# pse84_a0 register map
Vendor: Infineon Technologies; Series: PSE84_A0; File version: 1.0
CPU: CM33 r0p1, little endian, MPU, FPU, VTOR, 3 interrupt priority bits
Registers are 32-bit, read-write, reset 0x0 unless marked. A register's access mark holds for its fields unless they carry their own. Offsets are from the block's base; [hi:lo] are bit positions; lines under a group give offsets from that group.

## USBHS (part 1 of 7) — Regmap for both Subsystem and Controller IP
Base 0x44900000
0x00 DWC_OTG_INTREG group — Internal register map
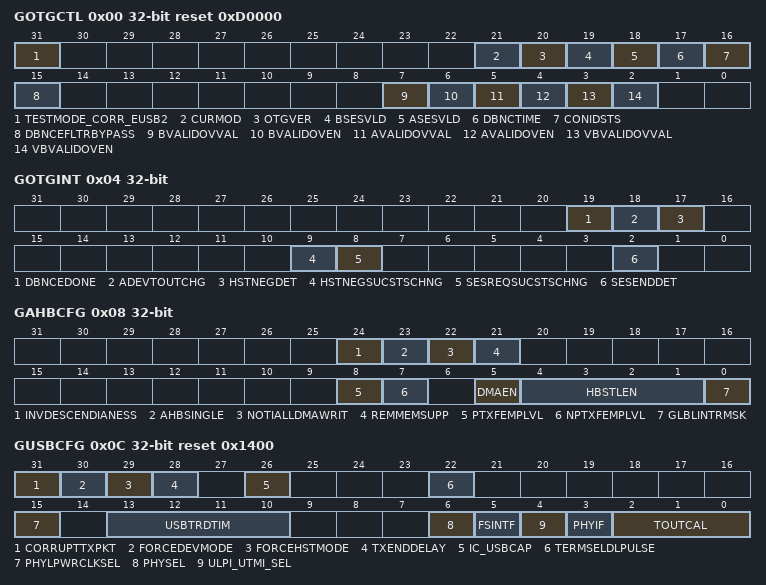
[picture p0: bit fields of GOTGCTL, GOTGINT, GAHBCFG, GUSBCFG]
  0x00 GOTGCTL reset 0xD0000 — The OTG Control and Status register controls the behavior and reflects the status of the OTG function of the controller.
    [31] TESTMODE_CORR_EUSB2 — UTMI IF correction for eUSB2 PHY during Test mode This bit is used to modify the behavior of UTMI 8-bit interface signals during test J and test K sequences when eUSB2 PHY is used. When this bit is set to 1'b1, the controller asserts utmi_txvalid and utmi_opmode in the same cycle during test J or test K sequence execution. Note: This bit is applicable only if eUSB2 PHY is used with 8-bit UTMI interface.
      0=eUSB2_corr_disable (The controller asserts utmi_txvalid one cycle later than utmi_opmode.); 1=eUSB2_corr_enable (The controller asserts utmi_txvalid and utmi_opmode in the same cycle.)
    [21] CURMOD ro — Current Mode of Operation (CurMod) Mode: Host and Device Indicates the current mode. - 1'b0: Device mode - 1'b1: Host mode Reset: - 1'b1 in Host-only mode (OTG_MODE=5 or 6) - 1'b0 in all other configurations Note: The reset value of this register field can be read only after the PHY clock is stable, or if IDDIG_FILTER is enabled, wait for the filter timer to expire to read the correct reset value which ever event is later.
      0=DEVICEMODE (Current mode is device mode.); 1=HOSTMODE (Current mode is host mode.)
    [20] OTGVER — OTG Version (OTGVer) Indicates the OTG revision. - 1'b0: OTG Version 1.3. In this version the core supports Data line pulsing and VBus pulsing for SRP. - 1'b1: OTG Version 2.0. In this version the core supports only Data line pulsing for SRP.
      0=VER13 (Supports OTG Version 1.3); 1=VER20 (Supports OTG Version 2.0)
    [19] BSESVLD ro — Mode: Device only B-Session Valid (BSesVld) Indicates the Device mode transceiver status. - 1'b0: B-session is not valid. - 1'b1: B-session is valid. In OTG mode, you can use this bit to determine if the device is connected or disconnected. Note: - If you do not enable OTG features (such as SRP and HNP), the read reset value will be 1.The vbus assigns the values internally for non- SRP or non-HNP configurations. - In case of OTG_MODE=0, the reset value of this bit is 1'b0. - The reset value of this register field can be read only after the PHY clock is stable, or if IDDIG_FILTER is enabled, wait for the filter timer to expire to read the correct reset value which ever event is later.
      0=NOTVALID (B-session is not valid.); 1=VALID (B-session is valid.)
    [18] ASESVLD ro — Mode: Host only A-Session Valid (ASesVld) Indicates the Host mode transceiver status. - 1'b0: A-session is not valid - 1'b1: A-session is valid Note: If you do not enabled OTG features (such as SRP and HNP), the read reset value will be 1. The vbus assigns the values internally for non-SRP or non-HNP configurations. In case of OTG_MODE=0, the reset value of this bit is 1'b0.
      0=NOTVALID (A-session is not valid.); 1=VALID (A-session is valid.)
    [17] DBNCTIME ro — Mode: Host only Long/Short Debounce Time (DbncTime) Indicates the debounce time of a detected connection. - 1'b0: Long debounce time, used for physical connections (100 ms + 2.5 micro-sec) - 1'b1: Short debounce time, used for soft connections (2.5 micro-sec)
      0=LONG (Long debounce time, used for physical connections (100 ms + 2.5 micro-sec)); 1=SHORT (Short debounce time, used for soft connections (2.5 micro-sec))
    [16] CONIDSTS ro — Mode: Host and Device Connector ID Status (ConIDSts) Indicates the connector ID status on a connect event. - 1'b0: The core is in A-Device mode. - 1'b1: The core is in B-Device mode. Note: The reset value of this register field can be read only after the PHY clock is stable, or if IDDIG_FILTER is enabled, wait for the filter timer to expire to read the correct reset value which ever event is later. Reset: - 1'b0: in host only mode (OTG_MODE = 5 or 6) - 1'b1: in all other configurations
      0=MODEA (The core is in A-Device mode.); 1=MODEB (The core is in B-Device mode.)
    [15] DBNCEFLTRBYPASS — Mode: Host and Device Debounce Filter Bypass Bypass Debounce filters for avalid, bvalid, vbusvalid, sessend, iddig signals when enabled. - 1'b0: Disabled - 1'b1: Enabled Note: This register bit is valid only when debounce filters are present in core.
      0=DISABLED (Debounce Filter Bypass is disabled.); 1=ENABLED (Debounce Filter Bypass is enabled.)
    [7] BVALIDOVVAL — Mode: Device only B-Peripheral Session Valid OverrideValue (BvalidOvVal) This bit is used to set Override value for Bvalid signal when GOTGCTL.BvalidOvEn is set. - 1'b0 : Bvalid value is 1'b0 when GOTGCTL.BvalidOvEn =1 - 1'b1 : Bvalid value is 1'b1 when GOTGCTL.BvalidOvEn =1
      0=Bvalid value when GOTGCTL.BvalidOvEn =1; 1=Bvalid value when GOTGCTL.BvalidOvEn =1
    [6] BVALIDOVEN — Mode: Device only B-Peripheral Session Valid Override Value (BvalidOvEn) This bit is used to enable/disable the software to override the Bvalid signal using the GOTGCTL.BvalidOvVal. - 1'b1 : Internally Bvalid received from the PHY is overridden with GOTGCTL.BvalidOvVal. - 1'b0 : Override is disabled and bvalid signal from the respective PHY selected is used internally by the force
      0=DISABLED (Override is disabled and bvalid signal from the respective PHY selected is used internally by the core); 1=ENABLED (Internally Bvalid received from the PHY is overridden with GOTGCTL.BvalidOvVal)
    [5] AVALIDOVVAL — Mode: Host only A-Peripheral Session Valid OverrideValue (AvalidOvVal) This bit is used to set Override value for Avalid signal when GOTGCTL.AvalidOvEn is set. - 1'b0 : Avalid value is 1'b0 when GOTGCTL.AvalidOvEn =1 - 1'b1 : Avalid value is 1'b1 when GOTGCTL.AvalidOvEn =1
      0=Avalid value is 1'b0 when GOTGCTL.AvalidOvEn =1; 1=Avalid value is 1'b1 when GOTGCTL.AvalidOvEn =1
    [4] AVALIDOVEN — Mode: Host only A-Peripheral Session Valid Override Enable (AvalidOvEn) This bit is used to enable/disable the software to override the Avalid signal using the GOTGCTL.AvalidOvVal. - 1'b1: Internally Avalid received from the PHY is overridden with GOTGCTL.AvalidOvVal. - 1'b0: Override is disabled and avalid signal from the respective PHY selected is used internally by the core
      0=DISABLED (Derive AValid from PHY); 1=ENABLED (Derive Avalid from GOTGCTL.AvalidOvVal)
    [3] VBVALIDOVVAL — Mode: Host only VBUS Valid OverrideValue (VbvalidOvVal) This bit is used to set Override value for vbusvalid signal when GOTGCTL.VbvalidOvEn is set. - 1'b0 : vbusvalid value is 1'b0 when GOTGCTL.VbvalidOvEn =1 - 1'b1 : vbusvalid value is 1'b1 when GOTGCTL.VbvalidOvEn =1
      0=SET0 (vbusvalid value when GOTGCTL.VbvalidOvEn = 1); 1=SET1 (vbusvalid value when GOTGCTL.VbvalidOvEn is 1)
    [2] VBVALIDOVEN — Mode: Host only VBUS Valid Override Enable (VbvalidOvEn) This bit is used to enable/disable the software to override the Bvalid signal using the GOTGCTL.VbvalidOvVal. - 1'b1 : Internally Bvalid received from the PHY is overridden with GOTGCTL.VbvalidOvVal. - 1'b0 : Override is disabled and bvalid signal from the respective PHY selected is used internally by the controller.
      0=DISABLED (Override is disabled and bvalid signal from the respective PHY selected is used internally by the controller); 1=ENABLED (The vbus-valid signal received from the PHY is overridden with GOTGCTL.VbvalidOvVal)
  0x04 GOTGINT — The application reads this register whenever there is an OTG interrupt and clears the bits in this register to clear the OTG interrupt.
    [19] DBNCEDONE — Mode: Host only Debounce Done (DbnceDone) The core sets this bit when the debounce is completed after the device connect. The application can start driving USB reset after seeing this interrupt. This bit is only valid when the HNP Capable or SRP Capable bit is SET in the Core USB Configuration register (GUSBCFG.HNPCap or GUSBCFG.SRPCap, respectively). This bit can be set only by the core and the application should write 1 to clear it.
      1=ACTIVE (Debounce completed); 0=INACTIVE (After Connect waiting for Debounce to complete)
    [18] ADEVTOUTCHG — Mode: Host and Device A-Device Timeout Change (ADevTOUTChg) The core sets this bit to indicate that the A-device has timed out while waiting for the B-device to connect.This bit can be set only by the core and the application should write 1 to clear it.
      1=ACTIVE (A-Device Timeout); 0=INACTIVE (No A-Device Timeout)
    [17] HSTNEGDET — Mode:Host and Device Host Negotiation Detected (HstNegDet) The core sets this bit when it detects a host negotiation request on the USB. This bit can be set only by the core and the application should write 1 to clear it.
      1=ACTIVE (Active HNP request detected); 0=INACTIVE (No Active HNP Request)
    [9] HSTNEGSUCSTSCHNG — Mode: Host and Device Host Negotiation Success Status Change (HstNegSucStsChng) The core sets this bit on the success or failure of a USB host negotiation request. The application must read the Host Negotiation Success bit of the OTG Control and Status register (GOTGCTL.HstNegScs) to check for success or failure. This bit can be set only by the core and the application should write 1 to clear it.
      1=ACTIVE (Host Negotiation Status Change); 0=INACTIVE (No Change)
    [8] SESREQSUCSTSCHNG — Mode: Host and Device Session Request Success Status Change (SesReqSucStsChng) The core sets this bit on the success or failure of a session request. The application must read the Session Request Success bit in the OTG Control and Status register (GOTGCTL.SesReqScs) to check for success or failure. This bit can be set only by the core and the application should write 1 to clear it.
      1=ACTIVE (Session Request Status has changed); 0=INACTIVE (No Change in Session Request Status)
    [2] SESENDDET — Mode: Host and Device Session End Detected (SesEndDet) The controller sets this bit when the utmiotg_bvalid signal is deasserted. This bit can be set only by the core and the application should write 1 to clear it.
      1=ACTIVE (SessionEnd utmiotg_bvalid signal is deasserted); 0=INACTIVE (Session is Active)
  0x08 GAHBCFG — This register can be used to configure the core after power-on or a change in mode. This register mainly contains AHB system-related configuration parameters. Do not change this register after the initial programming. The application must program this register before starting any transactions on either the AHB or the USB.
    [24] INVDESCENDIANESS — Mode: Host and Device Invert Descriptor Endianess (InvDescEndianess) - 1'b0: Descriptor Endianness is same as AHB Master Endianness. - 1'b1: -- If the AHB Master endianness is Big Endian, the Descriptor Endianness is Little Endian. -- If the AHB Master endianness is Little Endian, the Descriptor Endianness is Big Endian.
      0=DISABLE (Descriptor Endianness is same as AHB Master Endianness); 1=ENABLE (Descriptor Endianness is opposite to AHB Master Endianness)
    [23] AHBSINGLE — Mode: Host and Device AHB Single Support (AHBSingle) This bit when programmed supports Single transfers for the remaining data in a transfer when the core is operating in DMA mode. - 1'b0: The remaining data in the transfer is sent using INCR burst size. - 1'b1: The remaining data in the transfer is sent using Single burst size. Note: If this feature is enabled, the AHB RETRY and SPLIT transfers still have INCR burst type. Enable this feature when the AHB Slave connected to the core does not support INCR burst (and when Split, and Retry transactions are not being used in the bus).
      0=INCRBURST (The remaining data in the transfer is sent using INCR burst size); 1=SINGLEBURST (The remaining data in the transfer is sent using Single burst size)
    [22] NOTIALLDMAWRIT — Mode: Host and Device Notify All DMA Write Transactions (NotiAllDmaWrit) This bit is programmed to enable the System DMA Done functionality for all the DMA write Transactions corresponding to the Channel/Endpoint. This bit is valid only when GAHBCFG.RemMemSupp is set to 1. - GAHBCFG.NotiAllDmaWrit = 1 The core asserts int_dma_req for all the DMA write transactions on the AHB interface along with int_dma_done, chep_last_transact and chep_number signal informations. The core waits for sys_dma_done signal for all the DMA write transactions in order to complete the transfer of a particular Channel/Endpoint. - GAHBCFG.NotiAllDmaWrit = 0 The core asserts int_dma_req signal only for the last transaction of DMA write transfer corresponding to a particular Channel/Endpoint. Similarly, the core waits for sys_dma_done signal only for that transaction of DMA write to complete the transfer of a particular Channel/Endpoint.
      1=ALLTRANS (The core asserts int_dma_req for all the DMA write transactions on the AHB interface along with int_dma_done, chep_last_transact and chep_number signal informations. The core waits for sys_dma_done signal for all the DMA write transactions in order to complete the transfer of a particular Channel/Endpoint); 0=LASTTRANS (N/A)
    [21] REMMEMSUPP — Mode: Host and Device Remote Memory Support (RemMemSupp) This bit is programmed to enable the functionality to wait for the system DMA Done Signal for the DMA Write Transfers. - GAHBCFG.RemMemSupp=1 The int_dma_req output signal is asserted when the DMA starts write transfer to the external memory. When the core is done with the Transfers it asserts int_dma_done signal to flag the completion of DMA writes from the controller. The core then waits for sys_dma_done signal from the system to proceed further and complete the Data Transfer corresponding to a particular Channel/Endpoint. - GAHBCFG.RemMemSupp=0 The int_dma_req and int_dma_done signals are not asserted and the core proceeds with the assertion of the XferComp interrupt as soon as the DMA write transfer is done at the Core Boundary and it does not wait for the sys_dma_done signal to complete the DATA transfers.
      0=DISABLED (Remote Memory Support Feature disabled); 1=ENABLED (Remote Memory Support Feature enabled)
    [8] PTXFEMPLVL — Mode: Host only Periodic TxFIFO Empty Level (PTxFEmpLvl) Indicates when the Periodic TxFIFO Empty Interrupt bit in the Core Interrupt register (GINTSTS.PTxFEmp) is triggered. This bit is used only in Slave mode. - 1'b0: GINTSTS.PTxFEmp interrupt indicates that the Periodic TxFIFO is half empty - 1'b1: GINTSTS.PTxFEmp interrupt indicates that the Periodic TxFIFO is completely empty
      1=EMPTY (GINTSTS.PTxFEmp interrupt indicates that the Periodic TxFIFO is completely empty.); 0=HALFEMPTY (GINTSTS.PTxFEmp interrupt indicates that the Periodic TxFIFO is half empty.)
    [7] NPTXFEMPLVL — Mode: Host and device Non-Periodic TxFIFO Empty Level (NPTxFEmpLvl) This bit is used only in Slave mode. In host mode and with Shared FIFO with device mode, this bit indicates when the Non-Periodic TxFIFO Empty Interrupt bit in the Core Interrupt register (GINTSTS.NPTxFEmp) is triggered. With dedicated FIFO in device mode, this bit indicates when IN endpoint Transmit FIFO empty interrupt (DIEPINTn.TxFEmp) is triggered. Host mode and with Shared FIFO with device mode: - 1'b0: GINTSTS.NPTxFEmp interrupt indicates that the Non-Periodic TxFIFO is half empty - 1'b1: GINTSTS.NPTxFEmp interrupt indicates that the Non-Periodic TxFIFO is completely empty Dedicated FIFO in device mode: - 1'b0: DIEPINTn.TxFEmp interrupt indicates that the IN Endpoint TxFIFO is half empty - 1'b1: DIEPINTn.TxFEmp interrupt indicates that the IN Endpoint TxFIFO is completely empty
      1=EMPTY (GINTSTS.NPTxFEmp interrupt indicates that the Non-Periodic TxFIFO is completely empty or that the IN Endpoint TxFIFO is completely empty.); 0=HALFEMPTY (DIEPINTn.TxFEmp interrupt indicates that the Non-Periodic TxFIFO is half empty or that the IN Endpoint TxFIFO is half empty.)
    [5] DMAEN — Mode: Host and device DMA Enable (DMAEn) This bit is always 0 when Slave-Only mode has been selected. Reset: 1'b0
      1=DMAMODE (Core operates in a DMA mode); 0=SLAVEMODE (Core operates in Slave mode)
    [4:1] HBSTLEN
      6=WORD128 (128 words); 3=WORD16ORINCR4 (16 words or INCR4); 0=WORD1ORSINGLE (1 word or single); 7=WORD256ORINCR16 (256 words or INCR16); 4=WORD32 (32 words); 1=WORD4ORINCR (4 words or INCR); 5=WORD64ORINCR8 (64 words or INCR8); 2=WORD8 (8 words); 8=WORDX (N/A)
    [0] GLBLINTRMSK — Mode: Host and device Global Interrupt Mask (GlblIntrMsk) The application uses this bit to mask or unmask the interrupt line assertion to itself. Irrespective of this bit's setting, the interrupt status registers are updated by the controller.
      0=MASK (Mask the interrupt assertion to the application); 1=NOMASK (Unmask the interrupt assertion to the application.)
  0x0C GUSBCFG reset 0x1400 — This register can be used to configure the core after power-on or when changing to Host mode or Device mode. It contains USB and USB-PHY related configuration parameters. The application must program this register before starting any transactions on either the AHB or the USB. If you are using the HSIC interface, HSIC PHY must be in reset while programming this register. Do not make changes to this register after the initial programming.
    [31] CORRUPTTXPKT wo — Mode: Host and device Corrupt Tx packet (CorruptTxPkt) This bit is for debug purposes only. Never Set this bit to 1. The application should always write 1'b0 to this bit.
      1=DEBUG (Debug Mode); 0=NODEBUG (Normal Mode)
    [30] FORCEDEVMODE — Mode:Host and device Force Device Mode (ForceDevMode) Writing a 1 to this bit forces the controller to device mode irrespective of utmiotg_iddig input pin. - 1'b0 : Normal Mode. - 1'b1 : Force Device Mode. After setting the force bit, the application must wait at least 25 ms before the change to take effect. When the simulation is in scale down mode, waiting for 500 micro sec is sufficient. This bit is valid only when OTG_MODE = 0, 1 or 2. In all other cases, this bit reads 0.
      0=DISABLED (Normal Mode); 1=ENABLED (Force Device Mode)
    [29] FORCEHSTMODE — Mode: Host and device Force Host Mode (ForceHstMode) Writing a 1 to this bit forces the core to host mode irrespective of utmiotg_iddig input pin. - 1'b0 : Normal Mode. - 1'b1 : Force Host Mode. After setting the force bit, the application must wait at least 25 ms before the change to take effect. When the simulation is in scale down mode, waiting for 500 micro sec is sufficient. This bit is valid only when OTG_MODE = 0, 1 or 2. In all other cases, this bit reads 0.
      0=DISABLED (Normal Mode); 1=ENABLED (Force Host Mode)
    [28] TXENDDELAY — Mode: Device only Tx End Delay (TxEndDelay) Writing 1'b1 to this bit enables the controller to follow the TxEndDelay timings as per UTMI+ specification 1.05 section 4.1.5 for opmode signal during remote wakeup. - 1'b0 : Normal Mode. - 1'b1 : Tx End delay.
      0=DISABLED (Normal Mode); 1=ENABLED (Tx End delay)
    [26] IC_USBCAP ro — Mode: Host and Device IC_USB-Capable (IC_USBCap) The application uses this bit to control the core's IC_USB capabilities. - 1'b0: IC_USB PHY Interface is not selected. - 1'b1: IC_USB PHY Interface is selected. This bit is writable only if OTG_ENABLE_IC_USB=1 and OTG_FSPHY_INTERFACE!=0. The reset value depends on the configuration parameter OTG_SELECT_IC_USB when OTG_ENABLE_IC_USB = 1. In all other cases, this bit is set to 1'b0 and the bit is read only.
      0=NOTSELECTED (IC_USB PHY Interface is not selected); 1=SELECTED (IC_USB PHY Interface is selected)
    [22] TERMSELDLPULSE — Mode: Device only TermSel DLine Pulsing Selection (TermSelDLPulse) This bit selects utmi_termselect to drive data line pulse during SRP. - 1'b0: Data line pulsing using utmi_txvalid (Default). - 1'b1: Data line pulsing using utmi_termsel.
      1=TERMSEL (Data line pulsing using utmi_termsel); 0=TXVALID (Data line pulsing using utmi_txvalid)
    [15] PHYLPWRCLKSEL — PHY Low-Power Clock Select (PhyLPwrClkSel) Mode: Host and Device Selects either 480-MHz or 48-MHz (low-power) PHY mode. In FS and LS modes, the PHY can usually operate on a 48-MHz clock to save power. - 1'b0: 480-MHz Internal PLL clock - 1'b1: 48-MHz External Clock In 480 MHz mode, the UTMI interface operates at either 60 or 30-MHz, depending upon whether 8- or 16-bit data width is selected. In 48-MHz mode, the UTMI interface operates at 48 MHz in FS mode and at either 48 or 6 MHz in LS mode (depending on the PHY vendor). This bit drives the utmi_fsls_low_power core output signal, and is valid only for UTMI+ PHYs.
      1=EXTCLK (48-MHz External Clock); 0=INTPLLCLK (480-MHz Internal PLL clock)
    [13:10] USBTRDTIM — Mode: Device only USB Turnaround Time (USBTrdTim) Sets the turnaround time in PHY clocks. Specifies the response time for a MAC request to the Packet FIFO Controller (PFC) to fetch data from the DFIFO (SPRAM). This must be programmed to - 4'h5 : When the MAC interface is 16-bit UTMI+ - 4'h9 : When the MAC interface is 8-bit UTMI+ Note:Programing Guide Section 'Choosing the Value of GUSBCFG.USBTrdTim' consider mis-sampling into account whereas above values are without mis-sampling. During the AHB Clock Frequency selection, it is recommended to consider mis-sampling into account for USBTrdTim. Note: The previous values are calculated for the minimum AHB frequency of 30 MHz. USB turnaround time is critical for certification where long cables and 5-Hubs are used. If you need the AHB to run at less than 30 MHz, and if USB turnaround time is not critical, these bits can be programmed to a larger value.
      5=TURNTIME16BIT (MAC interface is 16-bit UTMI+.); 9=TURNTIME8BIT (MAC interface is 8-bit UTMI+.)
    [6] PHYSEL ro — PHYSel Mode: Host and Device USB 2.0 High-Speed PHY or USB 1.1 Full-Speed Serial Transceiver Select (PHYSel) The application uses this bit to select either a high-speed UTMI+ or ULPI PHY, or a full-speed transceiver. - 1'b0: USB 2.0 high-speed UTMI+ or ULPI PHY - 1'b1: USB 1.1 full-speed serial transceiver If a USB 1.1 Full-Speed Serial Transceiver interface was not selected in, this bit is always 0, with Write Only access. If a high-speed PHY interface was not selected in, this bit is always 1, with Write Only access. If both interface types were selected (parameters have non-zero values), the application uses this bit to select which interface is active, and access is Read and Write.
      1=USB11 (USB 1.1 full-speed serial transceiver is selected); 0=USB20 (USB 2.0 high-speed UTMI+ or ULPI PHY is selected)
    [5] FSINTF ro — Mode: Host and Device Full-Speed Serial Interface Select (FSIntf) The application uses this bit to select either a unidirectional or bidirectional USB 1.1 full-speed serial transceiver interface. - 1'b0: 6-pin unidirectional full-speed serial interface - 1'b1: 3-pin bidirectional full-speed serial interface If a USB 1.1 Full-Speed Serial Transceiver interface was not selected, this bit is always 0, with Write Only access. If a USB 1.1 FS interface was selected, Then the application can Set this bit to select between the 3- and 6-pin interfaces, and access is Read and Write. Note: For supporting the new 4-pin bi-directional interface, you need to select 6-pin unidirectional FS serial mode, and add an external control to convert it to a 4-pin interface.
      1=FS3PIN (3-pin bidirectional full-speed serial interface); 0=FS6PIN (6-pin unidirectional full-speed serial interface)
    [4] ULPI_UTMI_SEL ro — Mode: Host and Device ULPI or UTMI+ Select (ULPI_UTMI_Sel) The application uses this bit to select either a UTMI+ interface or ULPI Interface. - 1'b0: UTMI+ Interface - 1'b1: ULPI Interface
      1=ULPI (ULPI Interface); 0=UTMI (UTMI+ Interface)
    [3] PHYIF ro — Mode: Host and Device PHY Interface (PHYIf) The application uses this bit to configure the core to support a UTMI+ PHY with an 8- or 16-bit interface. When a ULPI PHY is chosen, this must be Set to 8-bit mode. - 1'b0: 8 bits - 1'b1: 16 bits This bit is writable only If UTMI+ and ULPI were selected. Otherwise, this bit returns the value for the power-on interface selected during configuration.
      1=BITS16 (PHY 16bit Mode); 0=BITS8 (PHY 8bit Mode)
    [2:0] TOUTCAL — Mode: Host and Device HS/FS Timeout Calibration (TOutCal) The number of PHY clocks that the application programs in this field is added to the high-speed/full-speed interpacket timeout duration in the core to account for any additional delays introduced by the PHY. This can be required, because the delay introduced by the PHY in generating the linestate condition can vary from one PHY to another. The USB standard timeout value for high-speed operation is 736 to 816 (inclusive) bit times. The USB standard timeout value for full-speed operation is 16 to 18 (inclusive) bit times. The application must program this field based on the speed of enumeration. The number of bit times added per PHY clock are as follows: High-speed operation: - One 30-MHz PHY clock = 16 bit times - One 60-MHz PHY clock = 8 bit times Full-speed operation: - One 30-MHz PHY clock = 0.4 bit times - One 60-MHz PHY clock = 0.2 bit times - One 48-MHz PHY clock = 0.25 bit times
      5=FIVE (Add 5 PHY clocks); 4=FOUR (Add 4 PHY clocks); 1=ONE (Add 1 PHY clocks); 7=SEVEN (Add 7 PHY clocks); 6=SIX (Add 6 PHY clocks); 3=THREE (Add 3 PHY clocks); 2=TWO (Add 2 PHY clocks); 0=ZERO (Add 0 PHY clocks)
